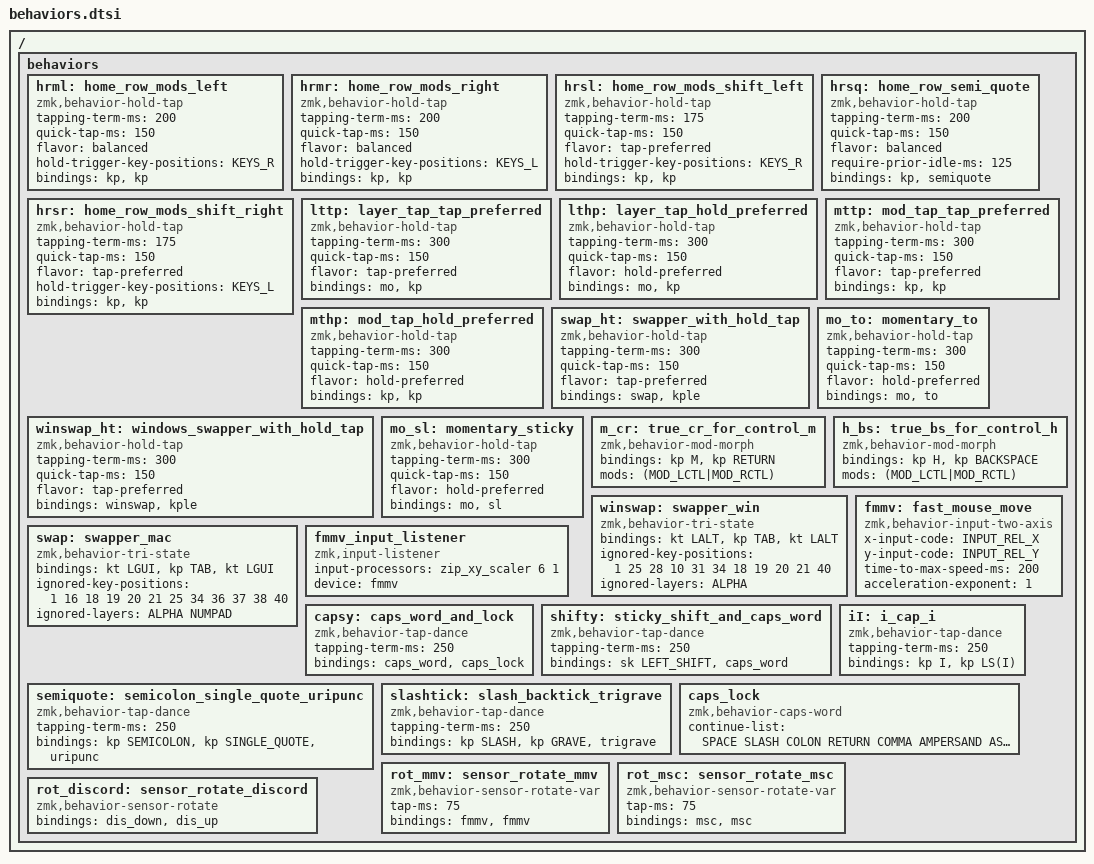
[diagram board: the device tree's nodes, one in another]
/ { 
	behaviors {
        hrml: home_row_mods_left {
            compatible = "zmk,behavior-hold-tap";
            #binding-cells = <2>;
            tapping-term-ms = <200>;
            quick-tap-ms = <150>;
            flavor = "balanced";
            //require-prior-idle-ms = <125>;
            hold-trigger-key-positions = < KEYS_R >;
            //hold-trigger-on-release; // delay positional check until key release
            bindings =
                <&kp>,
                <&kp>;
        };
        hrmr: home_row_mods_right {
            compatible = "zmk,behavior-hold-tap";
            #binding-cells = <2>;
            tapping-term-ms = <200>;
            quick-tap-ms = <150>;
            flavor = "balanced";
            //require-prior-idle-ms = <125>;
            hold-trigger-key-positions = < KEYS_L >;
            //hold-trigger-on-release; // delay positional check until key release
            bindings =
                <&kp>,
                <&kp>;
        };
        hrsl: home_row_mods_shift_left {
            compatible = "zmk,behavior-hold-tap";
            #binding-cells = <2>;
            tapping-term-ms = <175>;
            quick-tap-ms = <150>;
            flavor = "tap-preferred";
            //require-prior-idle-ms = <125>;
            hold-trigger-key-positions = < KEYS_R >;
            //hold-trigger-on-release; // delay positional check until key release
            bindings =
                <&kp>,
                <&kp>;
        };
        hrsr: home_row_mods_shift_right {
            compatible = "zmk,behavior-hold-tap";
            #binding-cells = <2>;
            tapping-term-ms = <175>;
            quick-tap-ms = <150>;
            flavor = "tap-preferred";
            //require-prior-idle-ms = <125>;
            hold-trigger-key-positions = < KEYS_L >;
            //hold-trigger-on-release; // delay positional check until key release
            bindings =
                <&kp>,
                <&kp>;
        };
        /omit-if-no-ref/ hrsq: home_row_semi_quote {
            compatible = "zmk,behavior-hold-tap";
            #binding-cells = <2>;
            tapping-term-ms = <200>;
            quick-tap-ms = <150>;
            flavor = "balanced";
            require-prior-idle-ms = <125>;
            //hold-trigger-key-positions = <list of all lhs keys>;
            //hold-trigger-on-release; // delay positional check until key release
            bindings =
                <&kp>,
                <&semiquote>;
        };
        lttp: layer_tap_tap_preferred {
            compatible = "zmk,behavior-hold-tap";
            #binding-cells = <2>;
            tapping-term-ms = <300>;
            quick-tap-ms = <150>;
            //require-prior-idle-ms = <125>;
            flavor = "tap-preferred";
            bindings =
                <&mo>,
                <&kp>;
        };
        lthp: layer_tap_hold_preferred {
            compatible = "zmk,behavior-hold-tap";
            #binding-cells = <2>;
            tapping-term-ms = <300>;
            quick-tap-ms = <150>;
            //require-prior-idle-ms = <125>;
            flavor = "hold-preferred";
            bindings =
                <&mo>,
                <&kp>;
        };
        mttp: mod_tap_tap_preferred {
            compatible = "zmk,behavior-hold-tap";
            #binding-cells = <2>;
            tapping-term-ms = <300>;
            quick-tap-ms = <150>;
            //require-prior-idle-ms = <125>;
            flavor = "tap-preferred";
            bindings =
                <&kp>,
                <&kp>;
        };
        mthp: mod_tap_hold_preferred {
            compatible = "zmk,behavior-hold-tap";
            #binding-cells = <2>;
            tapping-term-ms = <300>;
            quick-tap-ms = <150>;
            //require-prior-idle-ms = <125>;
            flavor = "hold-preferred";
            bindings =
                <&kp>,
                <&kp>;
        };
        swap_ht: swapper_with_hold_tap {
            compatible = "zmk,behavior-hold-tap";
            #binding-cells = <2>;
            tapping-term-ms = <300>;
            quick-tap-ms = <150>;
            flavor = "tap-preferred";
            bindings =
                <&swap>,
                <&kple>;
        };
        winswap_ht: windows_swapper_with_hold_tap {
            compatible = "zmk,behavior-hold-tap";
            #binding-cells = <2>;
            tapping-term-ms = <300>;
            quick-tap-ms = <150>;
            flavor = "tap-preferred";
            bindings =
                <&winswap>,
                <&kple>;
        };
        mo_to: momentary_to {
            compatible = "zmk,behavior-hold-tap";
            #binding-cells = <2>;
            tapping-term-ms = <300>;
            quick-tap-ms = <150>;
            flavor = "hold-preferred";
            bindings =
                <&mo>,
                <&to>;
        };
        mo_sl: momentary_sticky {
            compatible = "zmk,behavior-hold-tap";
            #binding-cells = <2>;
            tapping-term-ms = <300>;
            quick-tap-ms = <150>;
            flavor = "hold-preferred";
            bindings =
                <&mo>,
                <&sl>;
        };
        m_cr: true_cr_for_control_m {
            compatible = "zmk,behavior-mod-morph";
            #binding-cells = <0>;
            bindings =
                <&kp M>,
                <&kp RETURN>;
            mods = <(MOD_LCTL|MOD_RCTL)>;
        };
        h_bs: true_bs_for_control_h {
            compatible = "zmk,behavior-mod-morph";
            #binding-cells = <0>;
            bindings =
                <&kp H>,
                <&kp BACKSPACE>;
            mods = <(MOD_LCTL|MOD_RCTL)>;
        };
        winswap: swapper_win {
            compatible = "zmk,behavior-tri-state";
            #binding-cells = <0>;
            bindings =
                <&kt LALT>,
                <&kp TAB>,
                <&kt LALT>;
            ignored-key-positions = <1 25 28 10 31 34 18 19 20 21 40>;
            ignored-layers = <ALPHA>;
        };
        swap: swapper_mac {
            compatible = "zmk,behavior-tri-state";
            #binding-cells = <0>;
            bindings =
                <&kt LGUI>,
                <&kp TAB>,
                <&kt LGUI>;
            // must include activating combo keys too (16 25, 19 34) or else tri-state will complete immediately for Mac
            // include hjkl (18 19 20 21) and nav layer activation (40) for navigation
            // include mode keys: h to hide (18), q to quit (1)
            // include lhs arrow key shortcuts: 36, 37, 38
            ignored-key-positions = <1 16 18 19 20 21 25 34 36 37 38 40>;
            ignored-layers = <ALPHA NUMPAD>;
        };
        /omit-if-no-ref/ fmmv: fast_mouse_move {
            compatible = "zmk,behavior-input-two-axis";
            #binding-cells = <1>;
            x-input-code = <INPUT_REL_X>;
            y-input-code = <INPUT_REL_Y>;
            time-to-max-speed-ms = <200>;
            acceleration-exponent = <1>;
        };
        fmmv_input_listener {
            compatible = "zmk,input-listener";
            input-processors = <&zip_xy_scaler 6 1>;
            device = <&fmmv>;
        };
        capsy: caps_word_and_lock {
            compatible = "zmk,behavior-tap-dance";
            #binding-cells = <0>;
            tapping-term-ms = <250>;
            bindings
                = <&caps_word>
                , <&caps_lock>
                ;
        };
        shifty: sticky_shift_and_caps_word {
            compatible = "zmk,behavior-tap-dance";
            #binding-cells = <0>;
            tapping-term-ms = <250>;
            bindings
                = <&sk LEFT_SHIFT>
                , <&caps_word>
                ;
        };
        iI: i_cap_i {
            compatible = "zmk,behavior-tap-dance";
            #binding-cells = <0>;
            tapping-term-ms = <250>;
            bindings = <&kp I>, <&kp LS(I)>;
        };
        /omit-if-no-ref/ semiquote: semicolon_single_quote_uripunc {
            compatible = "zmk,behavior-tap-dance";
            #binding-cells = <0>;
            tapping-term-ms = <250>;
            bindings = <&kp SEMICOLON>, <&kp SINGLE_QUOTE>, <&uripunc>;
        };
        /omit-if-no-ref/ slashtick: slash_backtick_trigrave {
            compatible = "zmk,behavior-tap-dance";
            #binding-cells = <0>;
            tapping-term-ms = <250>;
            bindings = <&kp SLASH>, <&kp GRAVE>, <&trigrave>;
        };
        caps_lock: caps_lock {
            compatible = "zmk,behavior-caps-word";
            #binding-cells = <0>;
            continue-list = <
SPACE SLASH COLON RETURN COMMA AMPERSAND ASTERISK TILDE BACKSLASH LESS_THAN GREATER_THAN LEFT_PARENTHESIS RIGHT_PARENTHESIS DOUBLE_QUOTES DOT DOLLAR PERCENT CARET TAB MINUS EQUAL LEFT_BRACE RIGHT_BRACE SINGLE_QUOTE EXCLAMATION AT POUND PIPE UNDERSCORE PLUS LEFT_BRACKET RIGHT_BRACKET GRAVE
            >;
        };
        /omit-if-no-ref/ rot_mmv: sensor_rotate_mmv {
            compatible = "zmk,behavior-sensor-rotate-var";
            #sensor-binding-cells = <2>;
            tap-ms = <75>;
            bindings = <&fmmv>, <&fmmv>;
        };
        /omit-if-no-ref/ rot_msc: sensor_rotate_msc {
            compatible = "zmk,behavior-sensor-rotate-var";
            #sensor-binding-cells = <2>;
            tap-ms = <75>;
            bindings = <&msc>, <&msc>;
        };
        /omit-if-no-ref/ rot_discord: sensor_rotate_discord {
            compatible = "zmk,behavior-sensor-rotate";
            #sensor-binding-cells = <0>;
            bindings = <&dis_down>, <&dis_up>;
        };

    };
};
